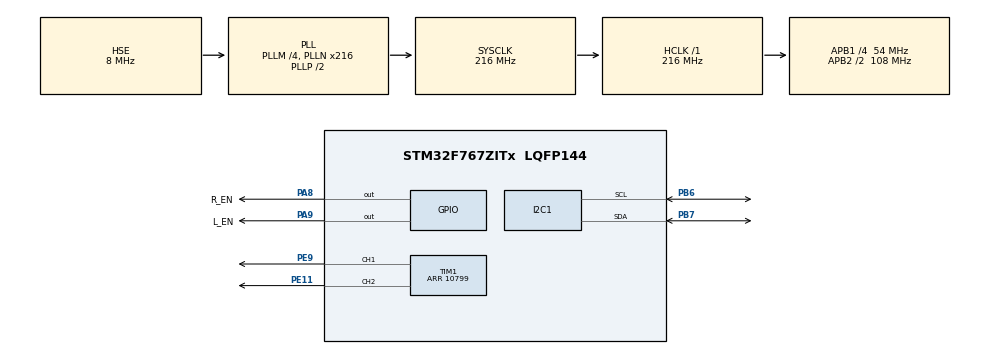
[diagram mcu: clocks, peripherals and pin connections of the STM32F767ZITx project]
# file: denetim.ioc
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I2C1.Timing=0x20404768
Mcu.Family=STM32F7
Mcu.Name=STM32F767ZITx
Mcu.Package=LQFP144
NVIC.PriorityGroup=NVIC_PRIORITYGROUP_4
PA8.GPIO_Label=R_EN
PA8.Signal=GPIO_Output
PA9.GPIO_Label=L_EN
PA9.Signal=GPIO_Output
PB6.Mode=I2C
PB6.Signal=I2C1_SCL
PB7.Mode=I2C
PB7.Signal=I2C1_SDA
PE11.Signal=S_TIM1_CH2
PE9.Signal=S_TIM1_CH1
PH0/OSC_IN.Mode=HSE-External-Oscillator
PH0/OSC_IN.Signal=RCC_OSC_IN
PH1/OSC_OUT.Mode=HSE-External-Oscillator
PH1/OSC_OUT.Signal=RCC_OSC_OUT
ProjectManager.HeapSize=0x200
ProjectManager.StackSize=0x400
ProjectManager.TargetToolchain=STM32CubeIDE
RCC.48MHZClocksFreq_Value=24000000
RCC.AHBFreq_Value=216000000
RCC.APB1CLKDivider=RCC_HCLK_DIV4
RCC.APB1Freq_Value=54000000
RCC.APB1TimFreq_Value=108000000
RCC.APB2CLKDivider=RCC_HCLK_DIV2
RCC.APB2Freq_Value=108000000
RCC.APB2TimFreq_Value=216000000
RCC.CortexFreq_Value=216000000
RCC.HCLKFreq_Value=216000000
RCC.HSE_VALUE=8000000
RCC.HSI_VALUE=16000000
RCC.LSE_VALUE=32768
RCC.PLLM=4
RCC.PLLMUL=RCC_PLL_MUL9
RCC.PLLN=216
RCC.PLLQ=4
RCC.PLLSourceVirtual=RCC_PLLSOURCE_HSE
RCC.PRESCALERUSB=RCC_USBCLKSOURCE_PLL_DIV1_5
RCC.SYSCLKFreq_VALUE=216000000
RCC.SYSCLKSource=RCC_SYSCLKSOURCE_PLLCLK
RCC.SYSCLKSourceVirtual=RCC_SYSCLKSOURCE_PLLCLK
RCC.USBFreq_Value=108000000
RCC.VCOOutputFreq_Value=432000000
SH.S_TIM1_CH1.0=TIM1_CH1,PWM Generation1 CH1
SH.S_TIM1_CH2.0=TIM1_CH2,PWM Generation2 CH2
TIM1.Channel-PWM\ Generation1\ CH1=TIM_CHANNEL_1
TIM1.Channel-PWM\ Generation2\ CH2=TIM_CHANNEL_2
TIM1.Period=10799
VP_TIM1_VS_ClockSourceINT.Mode=Internal
board=NUCLEO-F767ZI

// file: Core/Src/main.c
/* USER CODE BEGIN Header */
/**
  ******************************************************************************
  * @file           : main.c
  * @brief          : Main program body
  ******************************************************************************
  * @attention
  *
  * Copyright (c) 2026 STMicroelectronics.
  * All rights reserved.
  *
  * This software is licensed under terms that can be found in the LICENSE file
  * in the root directory of this software component.
  * If no LICENSE file comes with this software, it is provided AS-IS.
  *
  ******************************************************************************
  */
/* USER CODE END Header */
#include "main.h"
#include "i2c.h"
#include "tim.h"
#include "gpio.h"

/* USER CODE BEGIN Includes */
#include "as5600.h"
#include <stdint.h>
/* USER CODE END Includes */

/* USER CODE BEGIN PV */
AS5600_TypeDef *as5600;
//uint16_t angle = 0;
//float derece = 0;
//HAL_StatusTypeDef status;
//uint8_t mag_status = 0;
/* USER CODE END PV */

void SystemClock_Config(void);
/* USER CODE BEGIN PFP */

void PID_PositionControl(void);

/* USER CODE END PFP */

int main(void)
{

  /* MCU Configuration--------------------------------------------------------*/

  /* Reset of all peripherals, Initializes the Flash interface and the Systick. */
  HAL_Init();

  /* Configure the system clock */
  SystemClock_Config();

  /* Initialize all configured peripherals */
  MX_GPIO_Init();
  MX_I2C1_Init();
  MX_TIM1_Init();
  /* USER CODE BEGIN 2 */
  HAL_TIM_PWM_Start(&htim1, TIM_CHANNEL_1); // RPWM
  HAL_TIM_PWM_Start(&htim1, TIM_CHANNEL_2); // LPWM

  as5600 = AS5600_New();
  as5600 -> i2cHandle = &hi2c1;
  AS5600_Init(as5600);

//  AS5600_GetRawAngle(a, angle);
//  AS5600_G
  /* USER CODE END 2 */

  /* Infinite loop */
  while (1)
  {

    /* USER CODE BEGIN 3 */
//	  AS5600_GetAngle(as5600, &angle);
//	  HAL_Delay(100);

	  PID_PositionControl();

	  HAL_Delay(1);

//	  HAL_Delay(5000);
//
//	  __HAL_TIM_SET_COMPARE(&htim1, TIM_CHANNEL_1, 6000);
//	  __HAL_TIM_SET_COMPARE(&htim1, TIM_CHANNEL_2, 0);
//	  HAL_Delay(2000);
//
//	  __HAL_TIM_SET_COMPARE(&htim1, TIM_CHANNEL_1, 0);
//	  __HAL_TIM_SET_COMPARE(&htim1, TIM_CHANNEL_2, 6000);
//	  HAL_Delay(2000);
//
//	  __HAL_TIM_SET_COMPARE(&htim1, TIM_CHANNEL_1, 0);
//	  __HAL_TIM_SET_COMPARE(&htim1, TIM_CHANNEL_2, 0);
//	  HAL_Delay(2000);

//	  AS5600_GetRawAngle(as5600, &angle);
//	  derece = (angle * 360.0f) / 4096.0f;
//	  HAL_Delay(50);
  }
  /* USER CODE END 3 */
}

void SystemClock_Config(void)
{
  RCC_OscInitTypeDef RCC_OscInitStruct = {0};
  RCC_ClkInitTypeDef RCC_ClkInitStruct = {0};

  /** Configure the main internal regulator output voltage
  */
  __HAL_RCC_PWR_CLK_ENABLE();
  __HAL_PWR_VOLTAGESCALING_CONFIG(PWR_REGULATOR_VOLTAGE_SCALE1);

  /** Initializes the RCC Oscillators according to the specified parameters
  * in the RCC_OscInitTypeDef structure.
  */
  RCC_OscInitStruct.OscillatorType = RCC_OSCILLATORTYPE_HSE;
  RCC_OscInitStruct.HSEState = RCC_HSE_ON;
  RCC_OscInitStruct.PLL.PLLState = RCC_PLL_ON;
  RCC_OscInitStruct.PLL.PLLSource = RCC_PLLSOURCE_HSE;
  RCC_OscInitStruct.PLL.PLLM = 4;
  RCC_OscInitStruct.PLL.PLLN = 216;
  RCC_OscInitStruct.PLL.PLLP = RCC_PLLP_DIV2;
  RCC_OscInitStruct.PLL.PLLQ = 4;
  RCC_OscInitStruct.PLL.PLLR = 2;
  if (HAL_RCC_OscConfig(&RCC_OscInitStruct) != HAL_OK)
  {
    Error_Handler();
  }

  /** Activate the Over-Drive mode
  */
  if (HAL_PWREx_EnableOverDrive() != HAL_OK)
  {
    Error_Handler();
  }

  /** Initializes the CPU, AHB and APB buses clocks
  */
  RCC_ClkInitStruct.ClockType = RCC_CLOCKTYPE_HCLK|RCC_CLOCKTYPE_SYSCLK
                              |RCC_CLOCKTYPE_PCLK1|RCC_CLOCKTYPE_PCLK2;
  RCC_ClkInitStruct.SYSCLKSource = RCC_SYSCLKSOURCE_PLLCLK;
  RCC_ClkInitStruct.AHBCLKDivider = RCC_SYSCLK_DIV1;
  RCC_ClkInitStruct.APB1CLKDivider = RCC_HCLK_DIV4;
  RCC_ClkInitStruct.APB2CLKDivider = RCC_HCLK_DIV2;

  if (HAL_RCC_ClockConfig(&RCC_ClkInitStruct, FLASH_LATENCY_7) != HAL_OK)
  {
    Error_Handler();
  }
}

void Error_Handler(void)
{
  __disable_irq();
  while (1)
  {
  }
}
